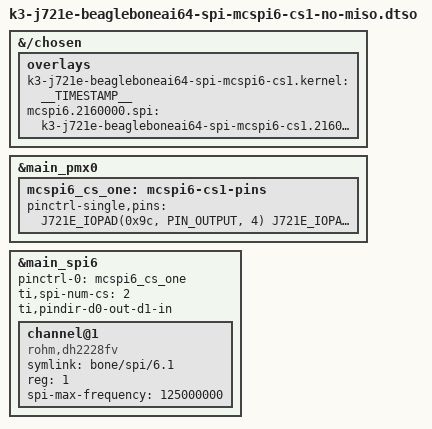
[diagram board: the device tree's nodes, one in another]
// SPDX-License-Identifier: GPL-2.0-only OR MIT
/*
 * DT Overlay for SPI6 pins P9_23(cs1), P9_22(clk), P9_21(MOSI).
 *
 * Copyright (C) 2023 Texas Instruments Incorporated - https://www.ti.com/
 *
 */

/dts-v1/;
/plugin/;

#include <dt-bindings/gpio/gpio.h>
#include "ti/k3-pinctrl.h"

/*
 * Helper to show loaded overlays under: /proc/device-tree/chosen/overlays/
*/
&{/chosen} {
        overlays {
                k3-j721e-beagleboneai64-spi-mcspi6-cs1.kernel = __TIMESTAMP__;
                mcspi6.2160000.spi = "k3-j721e-beagleboneai64-spi-mcspi6-cs1.2160000";
        };
};

/* To figure out which SoC pad numbers go with which BB header pins, look at columns A and B
 * in the following spreadsheet. To figure out mux modes, look at row 10.
 * https://drive.google.com/file/d/15NLaUeMBy-iT8s6rFrP4Esf0Qh57T4xu/view?pli=1
 *
 * To figure out the addresses of SoC pads, look at table "Table 5-125. Pin Multiplexing" in the TDA4VM Processors datasheet
 * https://www.ti.com/lit/ds/symlink/tda4vm.pdf?ts=1741890214437&ref_url=https%253A%252F%252Fwww.ti.com%252Fproduct%252FTDA4VM
 *

 * ~~ Walkthrough of process to figure out muxing ~~
 *
 * From the spreadsheet we see that pad AC22 is the first pad on BB header pin P9_22. AC22 is thus known as P9_22a. The alternative
 * pad, U29, is known as P9_22b. From Looking at the TDA4VM datasheet, we see that AC22(aka P9_22a) has the address 0x00011C09C. For 
 * the J721E_IOPAD() pin-mux macro, we need the bottom 24bits of the address, so 0x09c, or 0x9c. 
 * 
 * To mux AC22(aka P9_22a) to be SPI6_CLK, as figured out from the spreadsheet, we need to set AC22 to mux-mode 4. And since
 * a SPI clock is an output signal, the pin should be put set to PIN_OUTPUT mode.
 * So `J721E_IOPAD(0x9c, PIN_OUTPUT, 4)`
 * 
 * We will also need to disable the second SoC pad that shares the same BB header pin. The SoC pad known as pin P9_22b, or 
 * pad U29. Using the same process as walked through with pad AC22, you get the following:
 * `J721E_IOPAD(0x170, PIN_DISABLE, 7)`
 *
 * So to mux SPI6_CLK on BB pin P9_22:
 * J721E_IOPAD(0x9c, PIN_OUTPUT, 4)
 * J721E_IOPAD(0x170, PIN_DISABLE, 7)
 *
*/
&main_pmx0 {
	mcspi6_cs_one: mcspi6-cs1-pins {
		pinctrl-single,pins = <            
            /* Used TI SysConfig app to generate these, had manually adjust output modes */
            J721E_IOPAD(0x9c, PIN_OUTPUT, 4) /* (AC22) PRG1_PRU1_GPO17.SPI6_CLK P9_22a */
			/* J721E_IOPAD(0x74, PIN_OUTPUT, 4) */ /* (AC21) PRG1_PRU1_GPO7.SPI6_CS0 P9_17a */
			J721E_IOPAD(0xa0, PIN_OUTPUT, 4) /* (AJ22) PRG1_PRU1_GPO18.SPI6_D0 MOSI P9_21a */
			/* J721E_IOPAD(0xa4, PIN_INPUT, 4) */ /* (AH22) PRG1_PRU1_GPO19.SPI6_D1 MISO P9_18a */
            J721E_IOPAD(0x28, PIN_OUTPUT, 4) /* (AG20) PRG1_PRU1_GPO8.SPI6_CS1 P9_23 */

            /* Disable SoC pins that share same BB header pins */
            /* This pin conflics*/
            J721E_IOPAD(0x170, PIN_DISABLE, 7) /* (U29) disable P9_22b */
            /* J721E_IOPAD(0x1D0, PIN_DISABLE, 7) */ /* (AA3) disable P9_17b */
            J721E_IOPAD(0x16C, PIN_DISABLE, 7) /* (U28) disable P9_21b */
            /* J721E_IOPAD(0x1E4, PIN_DISABLE, 7) */ /* (Y2) disable P9_18b */
            /* No conflicting pad for P9_23 (AG20), so no disable needed */
		>;
	};
};

/* Most of the stuff in this section is here for the spidev linux driver. For control from
 * from a DSP or R5 core, only the status and pinctrl parts matter.
 *
 */
&main_spi6 {
    #address-cells = <1>;
    #size-cells = <0>;
    pinctrl-names = "default";
    pinctrl-0 = <&mcspi6_cs_one>;
    ti,spi-num-cs = <2>; /* With this number wrong, no spi device would get created, error seen with `sudo journalctl -k` */
    ti,pindir-d0-out-d1-in; /* d1 is not really an input, the pin is not muxed */
    status = "okay";

	/* When controlling SPI from outside linux, you may want to delete this spidev stuff */
    channel@1 {
        symlink = "bone/spi/6.1";
        compatible = "rohm,dh2228fv";
        reg = <1>; /* CE1 */
        spi-max-frequency = <125000000>;
    };
};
